# AT32F415 register map
Vendor: Keil; Series: AT32F415; File version: 1.0
CPU: CM4 r0p1, little endian, no MPU, FPU, 4 interrupt priority bits
Registers are 32-bit, read-write, reset 0x0 unless marked. A register's access mark holds for its fields unless they carry their own. Offsets are from the block's base; [hi:lo] are bit positions; {n}, {i} and the like mark numbered series; 'fields as' and 'values as' point back to an identical list.

## WWDT — Window watchdog
Base 0x40002C00
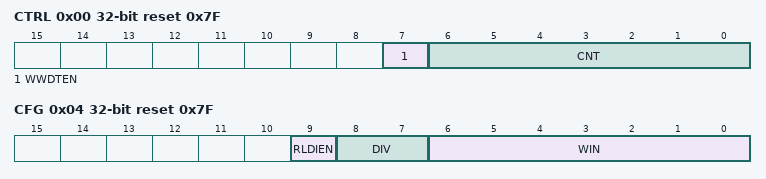
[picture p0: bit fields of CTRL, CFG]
0x00 CTRL reset 0x7F — Control register
  [7] WWDTEN write-1-sets — Window watchdog enable
    on read: 0=Disabled; 1=Enabled | on write: 1=Enable
  [6:0] CNT — Decrement counter
0x04 CFG reset 0x7F — Configuration register
  [9] RLDIEN — Reload counter interrupt
    on read: 0=Disabled; 1=Enabled | on write: 0=Disable; 1=Enable
  [8:7] DIV — Clock division value
    0=PCLK1 divided by 4096; 1=PCLK1 divided by 8192; 2=PCLK1 divided by 16384; 3=PCLK1 divided by 32768
  [6:0] WIN — Window value
0x08 STS — Status register
  [0] RLDF write-0-clears — Reload counter interrupt flag
    on read: 0=NotReached (Downcounter doesn't reached 0x40); 1=Reached (Downcounter reached 0x40) | on write: 0=Clear flag

## CMP — Comparator
Base 0x40002400
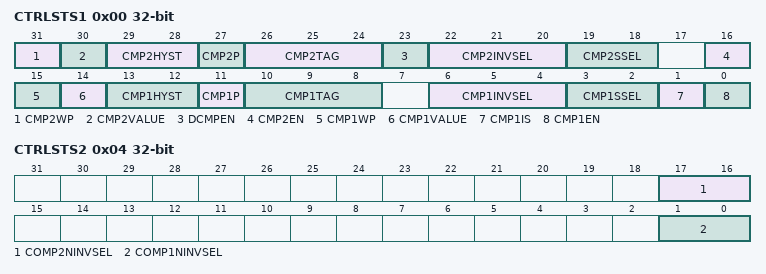
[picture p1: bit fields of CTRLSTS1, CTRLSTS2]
0x00 CTRLSTS1 — CMP control/status register1
  [31] CMP2WP — Comparator2 write protect
  [30] CMP2VALUE ro — Comparator2 output value
  [29:28] CMP2HYST — Comparator2 hysteresis
  [27] CMP2P — Comparator2 polarity
  [26:24] CMP2TAG — Comparator2 output target
  [23] DCMPEN — Double comparator mode enable
  [22:20] CMP2INVSEL — Comparator2 inverting selection
  [19:18] CMP2SSEL — Comparator2 speed selection
  [16] CMP2EN — Comparator2 enable bit
  [15] CMP1WP — Comparator1 write protect
  [14] CMP1VALUE ro — Comparator1 output value
  [13:12] CMP1HYST — Comparator1 hysteresis
  [11] CMP1P — Comparator1 polarity
  [10:8] CMP1TAG — Comparator1 output target
  [6:4] CMP1INVSEL — Comparator1 inverting selection
  [3:2] CMP1SSEL — Comparator1 speed selection
  [1] CMP1IS — Comparator1 input shift
  [0] CMP1EN — Comparator1 enable bit
0x04 CTRLSTS2 — CMP control/status register2
  [17:16] COMP2NINVSEL — Comparator2 non-inverting input selection
  [1:0] COMP1NINVSEL — Comparator1 non-inverting input selection

## DEBUG — Debug support
Base 0xE0042000
0x00 IDCODE ro — DEBUG IDCODE
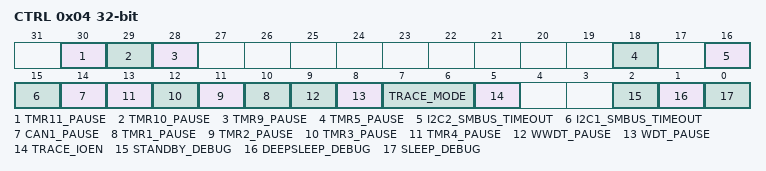
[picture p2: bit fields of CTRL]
0x04 CTRL — MCUDBG_CTRL
  [30] TMR11_PAUSE — Timer pause control bit
    0=Continue (The counter clock of TMRx is fed even if the core is halted); 1=Pause (The counter clock of TMRx is stopped when the core is halted)
  [29] TMR10_PAUSE — Timer pause control bit
    values as TMR11_PAUSE
  [28] TMR9_PAUSE — Timer pause control bit
    values as TMR11_PAUSE
  [18] TMR5_PAUSE — Timer pause control bit
    values as TMR11_PAUSE
  [16] I2C2_SMBUS_TIMEOUT
  [15] I2C1_SMBUS_TIMEOUT
  [14] CAN1_PAUSE
  [n+9] TMR{n}_PAUSE (n=1..4) — Timer pause control bit
    values as TMR11_PAUSE
  [9] WWDT_PAUSE
    values as TMR11_PAUSE
  [8] WDT_PAUSE
    values as TMR11_PAUSE
  [7:6] TRACE_MODE
  [5] TRACE_IOEN
  [2] STANDBY_DEBUG — Debug Standby mode control bit
    on read: 0=Disabled (The whole 1.2V digital circuit is unpowered in Standby mode); 1=Enabled (The whole 1.2V digital circuit is not unpowered in Standby mode, and the system clock is provided by the internal RC oscillator (HICK)) | on write: 0=Disable (The whole 1.2V digital circuit is unpowered in Standby mode); 1=Enable (The whole 1.2V digital circuit is not unpowered in Standby mode, and the system clock is provided by the internal RC oscillator (HICK))
  [1] DEEPSLEEP_DEBUG — Debug Deepsleep mode control bit
    on read: 0=Disabled (In Deepsleep mode, all clocks in the 1.2V domain are disabled); 1=Enabled (In Deepsleep mode, system clock is provided by the internal RC oscillator (HICK)) | on write: 0=Disable (In Deepsleep mode, all clocks in the 1.2V domain are disabled); 1=Enable (In Deepsleep mode, system clock is provided by the internal RC oscillator (HICK))
  [0] SLEEP_DEBUG — Debug Sleep mode control bit
    on read: 0=Disabled (When entering Sleep mode, CPU HCLK clock is disabled, but other clocks remain active); 1=Enabled (When entering Sleep mode, all clocks keep running) | on write: 0=Disable (When entering Sleep mode, CPU HCLK clock is disabled, but other clocks remain active); 1=Enable (When entering Sleep mode, all clocks keep running)
